# ISP6P5_IPIPE register map
Vendor: Texas Instruments
Peripheral module from a debugger description file (folder TDA2Px).
Registers are 32-bit, access per field, reset 0x0 unless marked. A register's access mark holds for its fields unless they carry their own. Offsets are as the file gives them; lines under a group give offsets from that group; [hi:lo] are bit positions; {n}, {i} and the like mark numbered series; 'fields as' and 'values as' point back to an identical list; <NAME> marks a mode.

## ISP6P5_IPIPE
0x00 IPIPE_SRC_EN — This register is not shadowed
  [0] EN rw — The start flag of the IPIPE module. When EN is 1, the IPIPE module starts a processing from the next rising edge of the VD. If the processing mode of the IPIPE module is ?one shot?, the EN is cleared to 0 immediately after the processing has started.
    0=NEWENUM1 (waiting); 1=NEWENUM2 (start/busy)
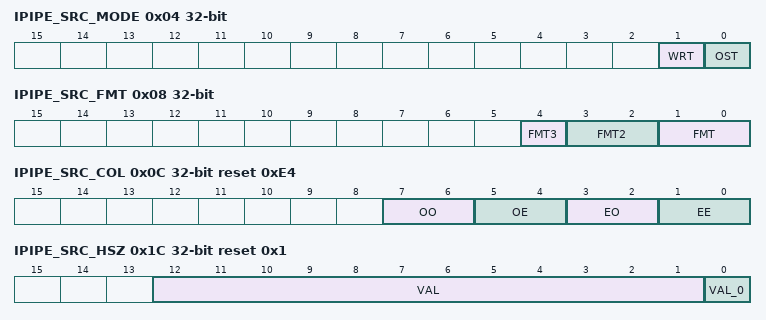
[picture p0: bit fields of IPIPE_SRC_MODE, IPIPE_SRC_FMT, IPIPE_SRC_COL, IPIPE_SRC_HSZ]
0x04 IPIPE_SRC_MODE
  [1] WRT rw — The mode selection of the ipipeif_wrt which is an input port of the IPIPE module. If WRT is 0, the IPIPE module doesn?t use the ipipeif_wrt. Else the IPIPE module uses it.
    0=NEWENUM1 (Disable); 1=NEWENUM2 (Enable)
  [0] OST rw — The processing mode selection of the IPIPE module. Value 0 indicates the mode of ?free run?, value 1 indicates the mode of ?one shot?.
    0=NEWENUM1 (Free run); 1=NEWENUM2 (One shot)
0x08 IPIPE_SRC_FMT
  [4] FMT3 rw — Chroma sumpling postion in YUV422 to 444 This field is only valide if FMT=3 and FT2=2
    0=COSITED (422 to 444 upsampling is processed assuming, chroma pixels are sampled at the same position as Y signals.); 1=CENTERED (422 to 444 upsampling is performed assuming chroma pixels are sampled at the center of two Y signals.)
  [3:2] FMT2 rw — YUV processing mode This field is valid only when FMT=3 (YUV input YUV output)
    0=YUV_PROCESS (Enhanced YUV mode is off. Only EdgeEnhancer, CAR, and CGS are enabled in YUV input); 1=YUV444_MODE (YUV422 input is upconverted to YUV444 422to444 is always used. GBCE, EdgeEnhancer, CAR, CGS, Histogram on YUV, BCS can be enabled.); 2=RGB_MODE (YUV422 input is converted to full color RGB YUVtoRGB (RGBtoRGB1 is used), Gamma (as non linear table), RGB2RGB2, 3DLUT, GBCE are used. EdgeEnhancer, CAR, CGS, Histogram on YUV, BSC can be enabled.)
  [1:0] FMT rw — IPIPE module datapath selection
    0=NEWENUM1 (IN: RAW BAYER OUT: YUV422 Note that the IPIPE YUV422 output goes to the RESIZER module where it can be further be converted in YUV420 or RGB format.); 1=NEWENUM2 (IN: RAW BAYER OUT: RAW BAYER The data are output after the White Balance module. It enables to bypass a large part of the IPIPE module.); 3=NEWENUM4 (IN: YUV422 OUT: YUV422 Note that the IPIPE YUV422 output goes to the RESIZER module where it can be further be converted in YUV420 or RGB format.); 2=NEWENUM3 (IN: RAW BAYER OUT: DISABLED The data are only going to BOXCAR and HISTOGRAM modules.)
0x0C IPIPE_SRC_COL reset 0xE4
  [all] fields
    0=NEWENUM1 (R); 1=NEWENUM2 (Gr); 3=NEWENUM4 (B); 2=NEWENUM3 (Gb)
  [7:6] OO rw — The color pattern of the odd line and odd pixel. This parameter is valid when IPIPE_SRC[FMT] is 0,1,2.
  [5:4] OE rw — The color pattern of the odd line and even pixel. This parameter is valid when IPIPE_SRC[FMT] is 0,1,2.
  [3:2] EO rw — The color pattern of the even line and odd pixel. This parameter is valid when IPIPE_SRC[FMT] is 0,1,2.
  [1:0] EE rw — The color pattern of the even line and even pixel. This parameter is valid when IPIPE_SRC[FMT] is 0,1,2.
0x10 IPIPE_SRC_VPS
  [15:0] VAL rw — The vertical position of the global frame from the rising edge of the VD. The IPIPE module will start an image processing from VAL line.
0x14 IPIPE_SRC_VSZ
  [12:0] VAL rw — The vertical size of the processing area. The VAL0 can not be written. The IPIPE module will process (VAL+1) lines.
0x18 IPIPE_SRC_HPS
  [15:0] VAL rw — The horizontal position of the global frame from the rising edge of the HD. The IPIPE module will start an image processing from VAL clock.
0x1C IPIPE_SRC_HSZ reset 0x1
  [12:1] VAL rw — The horizontal size of the processing area. The VAL0 is fixed. The IPIPE module processes (VAL+1) clocks.
  [0] VAL_0 ro — This is the LSB of the VAL[12:0]. This bit is read only.
0x20 IPIPE_SEL_SBU
  [0] EDOF rw — EDOF port selection
    0=INT (Not used This value must be selected for OMAP4/5/6); 1=EXT (Used Can not be selected for OMAP4/5/6)
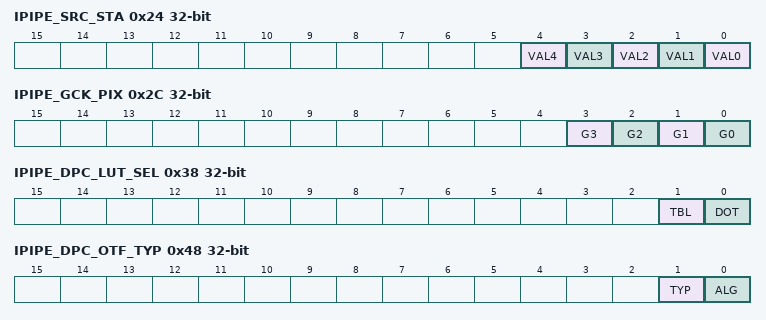
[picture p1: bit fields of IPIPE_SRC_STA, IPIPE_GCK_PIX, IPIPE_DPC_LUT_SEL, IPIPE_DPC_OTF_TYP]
0x24 IPIPE_SRC_STA ro — IPIPE STATUS REGISTER
  [4] VAL4 — Status of Histogram Process (busy status).
  [3] VAL3 — Status of Histogram bank select.
  [2] VAL2 — Status of BSC process (busy status).
  [1] VAL1 — Status of Boxcar process (busy status).
  [0] VAL0 — Status of Boxcar process (error status). This bit will be triggered when an overflow happens while transferring the boxcar data to memory. Instead of polling for this register, it is preferable to use the IPIPE_BOXCAR_OVF interrupt. Overflow errors are non receoverable at ISP5 level and require a software reset at ISS level.
0x28 IPIPE_GCK_MMR
  [0] REG rw — The on/off selection of the clk_arm_g0 which is used for some ARM register access.
    0=NEWENUM1 (Off); 1=NEWENUM2 (On)
0x2C IPIPE_GCK_PIX — This register is not shadowed
  [all] fields
    0=NEWENUM1 (Disable); 1=NEWENUM2 (Enable)
  [3] G3 rw — The on/off selection of the clk_pix_g3 which is use for the IPIPE processes of ?EE? and 'CAR'.
  [2] G2 rw — The on/off selection of the clk_pix_g2 which is use for the IPIPE processes of ?CFA? to '422', 'Histogram(YCbCr input)', and 'Boundary Signal Calculator'.
  [1] G1 rw — The on/off selection of the clk_pix_g1 which is used for the IPIPE processes of 'DefectCorrection' to 'WhiteBalance', and 'Histogram(RAW input)'.
  [0] G0 rw — The on/off selection of the clk_pix_g0 which is used for the IPIPE processing of 'Boxcar'.
0x34 IPIPE_DPC_LUT_EN
  [0] EN rw — Enable of LUT defect pixel correction.
    0=NEWENUM1 (Off); 1=NEWENUM2 (On)
0x38 IPIPE_DPC_LUT_SEL
  [1] TBL rw — LUT table type selection.
    0=NEWENUM1 (Up to 1024 entries. (use)); 1=NEWENUM2 (infinity number of entries. (not use))
  [0] DOT rw — Replace dot selection on processing method 0.
    0=NEWENUM1 (Replace with black dot); 1=NEWENUM2 (Replace with white dot)
0x3C IPIPE_DPC_LUT_ADR
  [9:0] ADR rw — The address of the first valid data in look-up-table
0x40 IPIPE_DPC_LUT_SIZ
  [9:0] SIZ rw — The number of valid data in look-up-table. (SIZ+1)
0x44 IPIPE_DPC_OTF_EN — Enable of adaptive defect pixel correction module.
  [0] EN rw
    0=NEWENUM1 (Off); 1=NEWENUM2 (On)
0x48 IPIPE_DPC_OTF_TYP — To select MinMax Algorithm following values are set ALG: 0 TYP: 0 IPIPE_DPC_OTF_2_D_THR_x: 0 IPIPE_DPC_OTF_2_C_THR_x: maximum value
  [1] TYP rw
    0=NEWENUM1 (with MAX1/MIN1.); 1=NEWENUM2 (with MAX2/MIN2.)
  [0] ALG rw
    0=NEWENUM1 (MinMax2 (DPC2.0)); 1=NEWENUM2 (MinMax3 (DPC3.0))
0x4C IPIPE_DPC_OTF_2_D_THR_R — D_THR for R
  [11:0] VAL rw — Defect detection threshold value for each color (DPC2.0)
0x50 IPIPE_DPC_OTF_2_D_THR_GR — D_THR for Gr
  fields as IPIPE_DPC_OTF_2_D_THR_R
0x54 IPIPE_DPC_OTF_2_D_THR_GB — D_THR for Gb
  fields as IPIPE_DPC_OTF_2_D_THR_R
0x58 IPIPE_DPC_OTF_2_D_THR_B — D_THR for B
  fields as IPIPE_DPC_OTF_2_D_THR_R
0x5C IPIPE_DPC_OTF_2_C_THR_R — C_THR for R
  [11:0] VAL rw — Defect correction threshold value for each color (DPC2.0)
0x60 IPIPE_DPC_OTF_2_C_THR_GR — C_THR for Gr
  fields as IPIPE_DPC_OTF_2_C_THR_R
0x64 IPIPE_DPC_OTF_2_C_THR_GB — C_THR for Gb
  fields as IPIPE_DPC_OTF_2_C_THR_R
0x68 IPIPE_DPC_OTF_2_C_THR_B — C_THR for B
  fields as IPIPE_DPC_OTF_2_C_THR_R
0x6C IPIPE_DPC_OTF_3_SHF
  [1:0] SHF rw
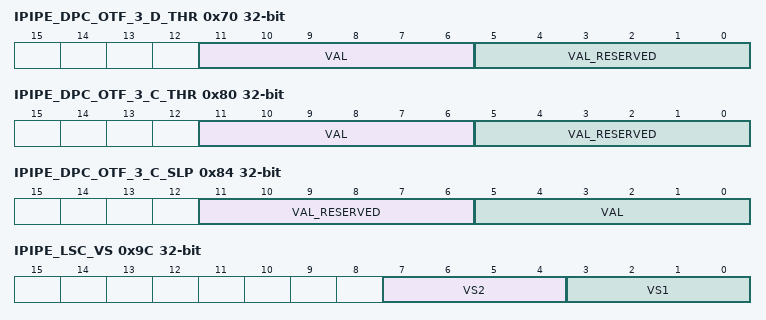
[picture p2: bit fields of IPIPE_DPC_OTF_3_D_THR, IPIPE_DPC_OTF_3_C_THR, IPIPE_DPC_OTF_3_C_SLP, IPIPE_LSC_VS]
0x70 IPIPE_DPC_OTF_3_D_THR
  [11:6] VAL rw — DPC3 Defect detection threshold 12-bit value. Bits [5:0] cannot be written.
  [5:0] VAL_RESERVED ro — DPC3 Defect detection threshold 12-bit value. Bits [5:0] cannot be written.
0x74 IPIPE_DPC_OTF_3_D_SPL
  [5:0] VAL rw — Defect detection threshold slope for DPC3.0
0x78 IPIPE_DPC_OTF_3_D_MIN
  [11:0] VAL rw
0x7C IPIPE_DPC_OTF_3_D_MAX
  [11:0] VAL rw — Defect detection threshold MAX for DPC3.0
0x80 IPIPE_DPC_OTF_3_C_THR
  [11:6] VAL rw — Defect correction threshold for DPC3.0
  [5:0] VAL_RESERVED ro — Defect correction threshold for DPC3.0 Bits VAL[5-0] cannot be written.
0x84 IPIPE_DPC_OTF_3_C_SLP
  [11:6] VAL_RESERVED ro — Defect correction threshold slope for DPC3.0 VAL[11-6] cannot be written.
  [5:0] VAL rw — Defect correction threshold slope for DPC3.0
0x88 IPIPE_DPC_OTF_3_C_MIN
  [11:0] VAL rw — Defect correction threshold MIN for DPC3.0
0x8C IPIPE_DPC_OTF_3_C_MAX
  [11:0] VAL rw — Defect correction threshold MAX for DPC3.0
0x90 IPIPE_LSC_VOFT — LSC VOFT
  [12:0] LSC_VOFT rw
0x94 IPIPE_LSC_VA2
  [12:0] VAL rw — LSC VA2
0x98 IPIPE_LSC_VA1
  [12:0] VAL rw — LSC VA1
0x9C IPIPE_LSC_VS
  [7:4] VS2 rw — LSC VS1
  [3:0] VS1 rw — LSC VS1
0xA0 IPIPE_LSC_HOFT
  [12:0] VAL rw — LSC HOFT
0xA4 IPIPE_LSC_HA2
  [12:0] VAL rw — LSC HA2
0xA8 IPIPE_LSC_HA1
  [12:0] VAL rw — LSC HA1
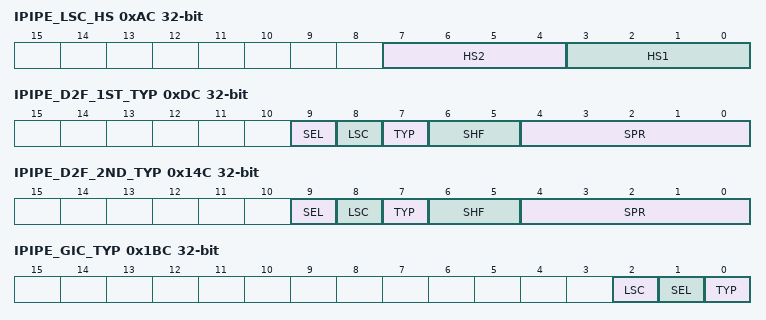
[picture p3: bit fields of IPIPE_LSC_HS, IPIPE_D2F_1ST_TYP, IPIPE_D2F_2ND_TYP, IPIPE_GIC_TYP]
0xAC IPIPE_LSC_HS
  [7:4] HS2 rw — LSC HS1
  [3:0] HS1 rw — LSC HS1
0xB0 IPIPE_LSC_GAN_R
  [7:0] VAL rw — GAN R
0xB4 IPIPE_LSC_GAN_GR
  [7:0] VAL rw — GAN GR
0xB8 IPIPE_LSC_GAN_GB
  [7:0] VAL rw — GAN GB
0xBC IPIPE_LSC_GAN_B
  [7:0] VAL rw — GAN B
0xC0 IPIPE_LSC_OFT_R
  [7:0] VAL rw — LSC OFT R
0xC4 IPIPE_LSC_OFT_GR
  [7:0] VAL rw — LSC OFT GR
0xC8 IPIPE_LSC_OFT_GB
  [7:0] VAL rw — LSC OFT GB
0xCC IPIPE_LSC_OFT_B
  [7:0] VAL rw — LSC OFT B
0xD0 IPIPE_LSC_SHF
  [3:0] VAL rw — LSC SHV
0xD4 IPIPE_LSC_MAX
  [8:0] VAL rw — LSC MAX
0xD8 IPIPE_D2F_1ST_EN — Noise Filter 1 Register
  [0] EN rw — Enable of noise filter-1 module.
    0=NEWENUM1 (off); 1=NEWENUM2 (on)
0xDC IPIPE_D2F_1ST_TYP — Noise Filter 1 Register
  [9] SEL rw — Select SPR value source
    0=NEWENUM1 (use single SPR value); 1=NEWENUM2 (use LUT SPR values)
  [8] LSC rw — Apply LSC gain to threshold values
    0=NEWENUM1 (off); 1=NEWENUM2 (on)
  [7] TYP rw — The sampling method of green pixels.
    0=NEWENUM1 (Box (same as R or B)); 1=NEWENUM2 (Diamond mode)
  [6:5] SHF rw — The d value (down shift value) in look-up-table reference address.
  [4:0] SPR rw — The SP value ('spread' value) in noise filter-1 algorithm.
{0xE0+4i} IPIPE_D2F_1ST_THR_{i:02} (i=0..7) — Noise Filter 1 Register
  [9:0] VAL rw — Threshold values in noise filter-1 algorithm.
{0x100+4i} IPIPE_D2F_1ST_STR_{i:02} (i=0..7) — Noise Filter 1 Register
  [4:0] VAL rw — Noise filter-1 intensity values (STR).
{0x120+4i} IPIPE_D2F_1ST_SPR_{i:02} (i=0..7) — Noise Filter 1 Register
  [4:0] VAL rw — Noise filter-1 intensity values (SP). The value is in U3.5 format.
0x140 IPIPE_D2F_1ST_EDG_MIN — Noise Filter 1 Register
  [10:0] VAL rw — Noise filter-1 edge detection MIN
0x144 IPIPE_D2F_1ST_EDG_MAX — Noise Filter 1 Register
  [10:0] VAL rw — Noise filter-1 edge detection MAX
0x148 IPIPE_D2F_2ND_EN — Noise Filter 2 Register
  [0] EN rw — Enable of noise filter-2 module.
    0=NEWENUM1 (off); 1=NEWENUM2 (on)
0x14C IPIPE_D2F_2ND_TYP — Noise Filter 2 Register
  [9] SEL rw — Select SPR value source
    values as IPIPE_D2F_1ST_TYP.SEL
  [8] LSC rw — Apply LSC gain to threshold values
    0=NEWENUM1 (off); 1=NEWENUM2 (on)
  [7] TYP rw — The sampling method of green pixels.
    0=NEWENUM1 (Box (Same as R or B)); 1=NEWENUM2 (Diamond mode)
  [6:5] SHF rw — The d value (down shift value) in look-up-table reference address.
  [4:0] SPR rw — The SP value ('spread' value) in noise filter-2 algorithm.
{0x150+4i} IPIPE_D2F_2ND_THR{i:02} (i=0..7) — Noise Filter 2 Register
  [9:0] VAL rw — Threshold values in noise filter-2 algorithm.
{0x170+4i} IPIPE_D2F_2ND_STR_{i:02} (i=0..7) — Noise Filter 2 Register
  [4:0] VAL rw — Noise filter-2 intensity values (STR).
{0x190+4i} IPIPE_D2F_2ND_SPR_{i:02} (i=0..7) — Noise Filter 2 Register
  [4:0] VAL rw — Noise filter-2 intensity values (SP). The value is in U3.5 format.
0x1B0 IPIPE_D2F_2ND_EDG_MIN — Noise Filter 2 Register
  [10:0] VAL rw — Noise filter-2 edge detection MIN
0x1B4 IPIPE_D2F_2ND_EDG_MAX — Noise Filter 2 Register
  [10:0] VAL rw — Noise filter-2 edge detection MAX
0x1B8 IPIPE_GIC_EN — Green Imbalance Correction Register
  [0] EN rw — Enable signal of PreFilter module
    0=NEWENUM1 (off); 1=NEWENUM2 (on)
0x1BC IPIPE_GIC_TYP — Green Imbalance Correction Register
  [2] LSC rw — Applies LSC gain to threshold value
    0=NEWENUM1 (Disable); 1=NEWENUM2 (Enable)
  [1] SEL rw — Threshold Selection This bit selects the threshold either from the register value (GIC_THR) or threshold table of NF-2
    0=NEWENUM1 (use GIC register value); 1=NEWENUM2 (use NF2 threshold)
  [0] TYP rw — Algorithm select
    0=NEWENUM1 (Use differencce as index); 1=NEWENUM2 (Use 1D high-pass value as index)
0x1C0 IPIPE_GIC_GAN — Green Imbalance Correction Register
  [7:0] VAL rw — VAL specifies the PreFilter gain.
0x1C4 IPIPE_GIC_NFGAIN
  [7:0] VAL rw
0x1C8 IPIPE_GIC_THR — Green Imbalance Correction Register
  [11:0] VAL rw — Threshold-1 in the adaptive GIC algorithm. For constant gain mode, setIPIPE_GIC_THR=maximum value.
0x1CC IPIPE_GIC_SLP — Green Imbalance Correction Register
  [11:0] VAL rw — Slope (THR2-THR1) of GIC algorithm.
0x1D0 IPIPE_WB2_OFT_R — White Balance Register
  [11:0] VAL rw — Offset before white balance (S12) -2048 to +2047
0x1D4 IPIPE_WB2_OFT_GR — White Balance Register
  [11:0] VAL rw — Offset before white balance (S12) -2048 to +2047
0x1D8 IPIPE_WB2_OFT_GB — White Balance Register
  [11:0] VAL rw — Offset before white balance (S12) -2048 to +2047
0x1DC IPIPE_WB2_OFT_B — White Balance Register
  [11:0] VAL rw — Offset before white balance (S12) -2048 to +2047
0x1E0 IPIPE_WB2_WGN_R reset 0x200 — White Balance Register
  [12:0] VAL rw — White balance gain for R in U4.9 format 0 to +15.998
0x1E4 IPIPE_WB2_WGN_GR reset 0x200 — White Balance Register
  [12:0] VAL rw — White balance gain for Gr in U4.9 format 0 to +15.998
0x1E8 IPIPE_WB2_WGN_GB reset 0x200 — White Balance Register
  [12:0] VAL rw — White balance gain for Gb in U4.9 format 0 to +15.998
0x1EC IPIPE_WB2_WGN_B reset 0x200 — White Balance Register
  [12:0] VAL rw — White balance gain for B in U4.9 format 0 to +15.998
0x1F0 IPIPE_CFA_MODE — CFA Register
  [1:0] MODE rw — Algorithm selection
    0=NEWENUM1 (2DirAC); 1=NEWENUM2 (2DirAC + DigitalAntialiasing (DAA)); 3=NEWENUM4 (Co-sited Bayer format Sets the CFA in co-sited Bayer format: the sampling points of R/Gr/Gb/B in each 2x2 block is at the same position. In this mode, the CFA interpolator simply copies R, G, and B to all points in the 2x2 block. (G is an average of Gb and Gr.)); 2=NEWENUM3 (DigitalAntialiasing (DAA))
0x1F4 IPIPE_CFA_2DIR_HPF_THR — CFA: HP Value Low Threshold
  [12:0] VAL rw — HPF_THR 2DirCFA HP Value Low Threshold
0x1F8 IPIPE_CFA_2DIR_HPF_SLP — CFA: HP Value Slope
  [9:0] VAL rw — HPF_SLP 2DirCFA HP Value Slope
0x1FC IPIPE_CFA_2DIR_MIX_THR — CFA: HP Mix Threshold
  [12:0] VAL rw — MIX_THR 2DirCFA HP Mix Threshold
0x200 IPIPE_CFA_2DIR_MIX_SLP — CFA Register
  [9:0] VAL rw — MIX_SLP 2DirCFA HP Mix Slope
0x204 IPIPE_CFA_2DIR_DIR_TRH — CFA: Direction Threshold
  [9:0] VAL rw — DIR_THR 2DirCFA Direction Threshold
0x208 IPIPE_CFA_2DIR_DIR_SLP — CFA: Direction Slope
  [6:0] VAL rw — DIR_SLP 2DirCFA Direction Slope
0x20C IPIPE_CFA_2DIR_NDWT
  [5:0] VAL rw — ND Weight 2DirCFA NonDirectional Weight
0x210 IPIPE_CFA_MONO_HUE_FRA — Mono CFA Register
  [5:0] VAL rw — HUE_FRA DAA Hue Fraction
0x214 IPIPE_CFA_MONO_EDG_THR — monoCFA THR SLP
  [7:0] VAL rw — EDGE_THR DAA Edge Threshold
0x218 IPIPE_CFA_MONO_THR_MIN — Mono CFA Register
  [9:0] VAL rw — THR_MIN DAA Threshold Minimum
0x21C IPIPE_CFA_MONO_THR_SLP — CFA: Threshold Slope
  [9:0] VAL rw — THR_SLP DAA Threshold Slope
0x220 IPIPE_CFA_MONO_SLP_MIN — CFA: Threshold Minimum
  [9:0] VAL rw — SLP_MIN DAA Slope Minimum
0x224 IPIPE_CFA_MONO_SLP_SLP — CFA: Threshold Slope
  [9:0] VAL rw — SLP_SLP DAA Slope Slope
0x228 IPIPE_CFA_MONO_LPWT — CFA: LP Weight
  [5:0] VAL rw — LPWT DAA LP Weight
0x22C IPIPE_RGB1_MUL_RR reset 0x100 — RGB to RGB Conversion Register
  [11:0] VAL rw — The matrix coefficient. 011111111111 = 2047/256 = 7.99609375 011111111110 = 2046/256 [...] 000011111111 = 255/256 000100000000 = 256/256 = 1 000100000001 = 257/256 [...] 000000000001 = 1/256 000000000000 = 0/256 = 0 111111111111 = -1/256 = -0.00390625 111111111110 = -2/256 [...] 100000000001 = -2047/256 100000000000 = -2048/256 = -8.
0x230 IPIPE_RGB1_MUL_GR — RGB to RGB Conversion Register
  [11:0] VAL rw — The matrix coefficient.
0x234 IPIPE_RGB1_MUL_BR — RGB to RGB Conversion Register
  [11:0] VAL rw — The matrix coefficient.
0x238 IPIPE_RGB1_MUL_RG — RGB to RGB Conversion Register
  [11:0] VAL rw — The matrix coefficient.
0x23C IPIPE_RGB1_MUL_GG reset 0x100 — RGB to RGB Conversion Register
  [11:0] VAL rw — The matrix coefficient.
0x240 IPIPE_RGB1_MUL_BG — RGB to RGB Conversion Register
  [11:0] VAL rw — The matrix coefficient.
0x244 IPIPE_RGB1_MUL_RB — RGB to RGB Conversion Register
  [11:0] VAL rw — The matrix coefficient.
0x248 IPIPE_RGB1_MUL_GB — RGB to RGB Conversion Register
  [11:0] VAL rw — The matrix coefficient.
0x24C IPIPE_RGB1_MUL_BB reset 0x100 — RGB to RGB Conversion Register
  [11:0] VAL rw — The matrix coefficient.
0x250 IPIPE_RGB1_OFT_OR — RGB to RGB Conversion Register
  [12:0] VAL rw — The output offset value for R. (s13) -4096 to +4095
0x254 IPIPE_RGB1_OFT_OG — RGB to RGB Conversion Register
  [12:0] VAL rw — The output offset value for G. (s13) -4096 to +4095
0x258 IPIPE_RGB1_OFT_OB — RGB to RGB Conversion Register
  [12:0] VAL rw — The output offset value for B. (s13) -4096 to +4095
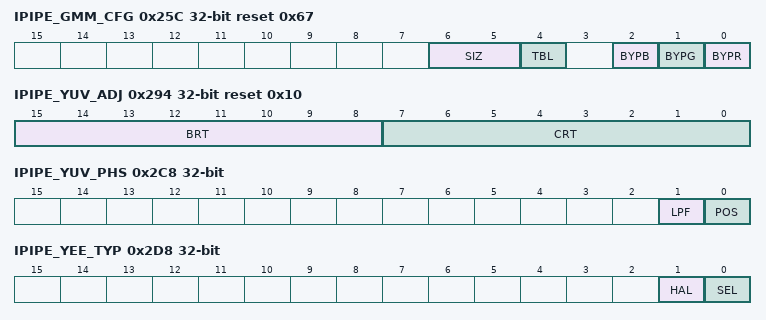
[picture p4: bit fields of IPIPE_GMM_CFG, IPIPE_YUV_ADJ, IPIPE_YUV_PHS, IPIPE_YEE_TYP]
0x25C IPIPE_GMM_CFG reset 0x67 — RGB to RGB Conversion Register
  [6:5] SIZ rw — The size of the gamma table.
    0=NEWENUM1 (64 words); 1=NEWENUM2 (128 words); 3=NEWENUM4 (512 words); 2=NEWENUM3 (256 words)
  [4] TBL rw — Selection of Gamma table.
    0=NEWENUM1 (RAM); 1=NEWENUM2 (ROM)
  [2] BYPB rw — Gamma correction mode for B
    0=NEWENUM1 (Not bypassed); 1=NEWENUM2 (Bypassed)
  [1] BYPG rw — Gamma correction mode for G
    0=NEWENUM1 (Not bypassed); 1=NEWENUM2 (Bypassed)
  [0] BYPR rw — Gamma correction mode for R
    0=NEWENUM1 (Not bypassed); 1=NEWENUM2 (Bypassed)
0x260 IPIPE_RGB2_MUL_RR reset 0x100 — RGB to RGB conversion after gamma
  [10:0] VAL rw — The matrix coefficient. 011111111111 = 2047/256 = 7.99609375 011111111110 = 2046/256 000011111111 = 255/256 000100000000 = 256/256 = 1 000100000001 = 257/256 000000000001 = 1/256 000000000000 = 0/256 = 0 111111111111 = -1/256 = -0.00390625 111111111110 = -2/256 100000000001 = -2047/256 100000000000 = -2048/256 = -8.
0x264 IPIPE_RGB2_MUL_GR — RGB to RGB conversion after gamma
  [10:0] VAL rw — The matrix coefficient.
0x268 IPIPE_RGB2_MUL_BR — RGB to RGB conversion after gamma
  [10:0] VAL rw — The matrix coefficient.
0x26C IPIPE_RGB2_MUL_RG — RGB to RGB conversion after gamma
  [10:0] VAL rw — The matrix coefficient.
0x270 IPIPE_RGB2_MUL_GG reset 0x100 — RGB to RGB conversion after gamma
  [10:0] VAL rw — The matrix coefficient.
0x274 IPIPE_RGB2_MUL_BG — RGB to RGB conversion after gamma
  [10:0] VAL rw — The matrix coefficient.
0x278 IPIPE_RGB2_MUL_RB — RGB to RGB conversion after gamma
  [10:0] VAL rw — The matrix coefficient.
0x27C IPIPE_RGB2_MUL_GB — RGB to RGB conversion after gamma
  [10:0] VAL rw — The matrix coefficient.
0x280 IPIPE_RGB2_MUL_BB reset 0x100 — RGB to RGB conversion after gamma
  [10:0] VAL rw — The matrix coefficient.
0x284 IPIPE_RGB2_OFT_OR — RGB to RGB conversion after gamma
  [10:0] VAL rw — The output offset value for R S10 number: -1024 to + 1023
0x288 IPIPE_RGB2_OFT_OG — RGB to RGB conversion after gamma
  [10:0] VAL rw — The output offset value for G S10 number: -1024 to + 1023
0x28C IPIPE_RGB2_OFT_OB — RGB to RGB conversion after gamma
  [10:0] VAL rw — The output offset value for B S10 number: -1024 to + 1023
0x290 IPIPE_3DLUT_EN — 3D-LUT
  [0] EN rw — Enables or disable the 3D-LUT function. The table entries are store in internal memory.
    0=NEWENUM1 (Disable); 1=NEWENUM2 (Enable)
0x294 IPIPE_YUV_ADJ reset 0x10 — RGB to YUV Conversion Register
  [15:8] BRT rw — The offset value for brightness control.
  [7:0] CRT rw — The multiplier coefficient value for contrast control. 00000000 = 0/16 = 0 00000001 = 1/16 00001111 = 15/16 00010000 = 16/16 = 1 00010001 = 17/16 11111110 = 254/16 11111111 = 255/16 = 15.9375
0x298 IPIPE_YUV_MUL_RY reset 0x4D — RGB to YUV Conversion Register
  [11:0] VAL rw — Matrix Coefficient for RY (S4.8 = -8 - +7.996)
0x29C IPIPE_YUV_MUL_GY reset 0x96 — RGB to YUV Conversion Register
  [11:0] VAL rw — Matrix Coefficient for GY (S4.8 = -8 - +7.996)
0x2A0 IPIPE_YUV_MUL_BY reset 0x1D — RGB to YUV Conversion Register
  [11:0] VAL rw — Matrix Coefficient for BY (S4.8 = -8 - +7.996)
0x2A4 IPIPE_YUV_MUL_RCB reset 0xFD5 — RGB to YUV Conversion Register
  [11:0] VAL rw — The matrix coefficient.
0x2A8 IPIPE_YUV_MUL_GCB reset 0xFAB — RGB to YUV Conversion Register
  [11:0] VAL rw — The matrix coefficient.
0x2AC IPIPE_YUV_MUL_BCB reset 0x80 — RGB to YUV Conversion Register
  [11:0] VAL rw — The matrix coefficient.
0x2B0 IPIPE_YUV_MUL_RCR reset 0x80 — RGB to YUV Conversion Register
  [11:0] VAL rw — The matrix coefficient.
0x2B4 IPIPE_YUV_MUL_GCR reset 0xF95 — RGB to YUV Conversion Register
  [11:0] VAL rw — The matrix coefficient.
0x2B8 IPIPE_YUV_MUL_BCR reset 0xFEB — RGB to YUV Conversion Register
  [11:0] VAL rw — The matrix coefficient.
0x2BC IPIPE_YUV_OFT_Y — RGB to YUV Conversion Register
  [10:0] VAL rw — The output offset value for Y
0x2C0 IPIPE_YUV_OFT_CB reset 0x80 — RGB to YUV Conversion Register
  [10:0] VAL rw — The output offset value for Cb For Cb/Cr, set (0x80 + offset value) here. (0x80 for zero offset.)
0x2C4 IPIPE_YUV_OFT_CR reset 0x80 — RGB to YUV Conversion Register
  [10:0] VAL rw — The output offset value for Cr For Cb/Cr, set (0x80 + offset value) here. (0x80 for zero offset.)
0x2C8 IPIPE_YUV_PHS — YUV422 down sampling register. This register controls the YUV444 to YUV422 chroma downsampling. This register is valid if.FMT = 0 (RAW input and YUV output). = 0 leads to pure subsampling, no filtering, cosited chroma output. = 1 leads to (1, 1) 1 filtering, centered chroma output. = 2 leads to (1, 2, 1) 1 filtering, cosited chroma output. = 3 leads to (1, 3, 3, 1) 3 filtering, centered chroma output. When the chroma output is cosited, and that downsampling is enabled in the RESIZER module, one need to take care that the averager disrupts the relative phase for luma and chroma color components. The and registers need to be used to fix the disruption.
  [1] LPF rw — 121-LPF enable for chrominance samples. This register is valid ifIPIPE_SRC_FMT.FMT = 0 (RAW input and YUV output).
    0=NEWENUM1 (off); 1=NEWENUM2 (on)
  [0] POS rw — This bit sets the output position of the chrominance sample with regards to the luma sample positions. One can choose between centered and cosited. This register is valid ifIPIPE_SRC_FMT.FMT = 0 (RAW input and YUV output). The RESIZER module does not change the relative position of the chroma samples vs. the luma samples between the input and output and the chroma position at the output of the IPIPE module and at the output of the RESIZER module shall be identical. In other words, we shall have RSZ_YUV_PHS.POS = IPIPE_YUV_PHS.POS.
    0=NEWENUM1 (Cosited = same position with luminance); 1=NEWENUM2 (Centered = middle of the luminance)
0x2CC IPIPE_GBCE_EN — Global brightness contrast enhancement
  [0] EN rw — Enable of GBCE module.
    0=NEWENUM1 (Off); 1=NEWENUM2 (On)
0x2D0 IPIPE_GBCE_TYP — Global brightness contrast enhancement
  [0] TYP rw — GBCE method selection
    0=NEWENUM1 (Y value table Y out= LUT[Y in] Cb out = Cb in Cr out = Cr in); 1=NEWENUM2 (Gain table Y out= LUT[Y in] * Y in Cb out = LUT[Y in] * Cb in Cr out = LUT[Y in] * Cr in)
0x2D4 IPIPE_YEE_EN — Edge Enhancer Register
  [0] EN rw — The on/off selection of the ?Edge enhancer?.
    0=NEWENUM1 (Disable); 1=NEWENUM2 (Enable)
0x2D8 IPIPE_YEE_TYP — Edge Enhancer Register
  [1] HAL rw — Halo reduction in Edge Sharpener module
  [0] SEL rw — Merging method between Edge Enhancer and Edge Sharpener
    0=NEWENUM2 (EE + ES); 1=NEWENUM1 (Max (EE, ES))
0x2DC IPIPE_YEE_SHF — Edge Enhancer Register
  [3:0] SHF rw — Down shift length of high pass filter (HPF) in edge enhancer.
0x2E0 IPIPE_YEE_MUL_00 — Edge Enhancer Register
  [9:0] VAL rw — Multiplier coefficient in HPF. 0111111111 = 511 0111111110 = 510 0000000001 = 1 0000000000 = 0 1111111111 = -1 1000000001 = -511 1000000000 = -512
0x2E4 IPIPE_YEE_MUL_01 — Edge Enhancer Register
  [9:0] VAL rw — Multiplier coefficient in HPF.
0x2E8 IPIPE_YEE_MUL_02 — Edge Enhancer Register
  [9:0] VAL rw — Multiplier coefficient in HPF.
{0x2C4+4i} IPIPE_YEE_MUL_{i} (i=10..12) — Edge Enhancer Register
  [9:0] VAL rw — Multiplier coefficient in HPF.
{0x2A8+4i} IPIPE_YEE_MUL_{i} (i=20..22) — Edge Enhancer Register
  [9:0] VAL rw — Multiplier coefficient in HPF.
0x304 IPIPE_YEE_THR — Edge Enhancer Register
  [5:0] VAL rw — Edge Enhancer lower threshold before referring to LUT. If HPF -IPIPE_YEE_THR - output is HPF + IPIPE_YEE_THR If HPF IPIPE_YEE_THR - output is HPF - IPIPE_YEE_THR Otherwise, output is zero.
0x308 IPIPE_YEE_E_GAN — Edge Enhancer Register
  [11:0] VAL rw — Edge sharpener gain
0x30C IPIPE_YEE_E_THR_1 — Edge Enhancer Register
  [11:0] VAL rw — Edge sharpener HPF value lower limit
0x310 IPIPE_YEE_E_THR_2 — Edge Enhancer Register
  [5:0] VAL rw — Edge sharpener HPF value upper limit (after 6 bit right shift)
0x314 IPIPE_YEE_G_GAN — Edge Enhancer Register
  [7:0] VAL rw — Edge sharpener, gain value on gradient
0x318 IPIPE_YEE_G_OFT — Edge Enhancer Register
  [5:0] VAL rw — Edge sharpener, offset value on gradient
0x31C IPIPE_CAR_EN — Chroma Artifact Reduction Register
  [0] EN rw — The on/off selection of the ?fault color suppression?. When the RSZ_SRC_FMT.FMT0='1' (Bayer input, Bayer output), this bit must be 0.
    0=NEWENUM1 (Disable); 1=NEWENUM2 (Enable)
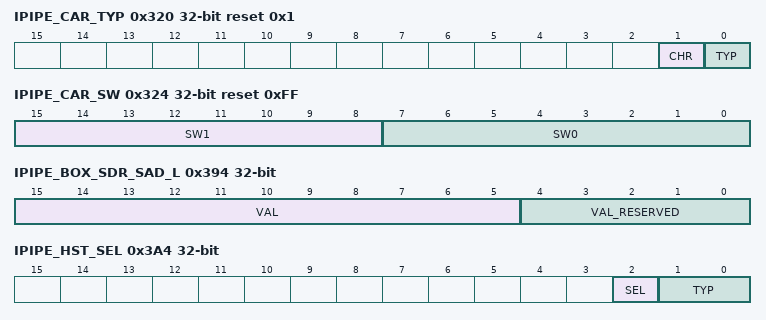
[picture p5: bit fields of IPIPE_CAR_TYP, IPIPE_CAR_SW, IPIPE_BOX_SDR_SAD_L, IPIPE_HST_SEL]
0x320 IPIPE_CAR_TYP reset 0x1 — Chroma Artifact Reduction Register
  [1] CHR rw — Note: This bit is added to OMAP5430 release and after. To specify the order of chroma in dynamic switching. This value should be zero unless Cb and Cr is flipped at RGBtoYCbCr/ 0: Normal Cb/Cr order (default) 1: Flipped order (Cr/Cb)
    0=NEWENUM1 (Default Chroma order (Cb/Cr).); 1=NEWENUM2 (Flipped chroma order (Cr/Cb). This value is used only when Cb and Cr are flipped in RGBtoYUV module.)
  [0] TYP rw — The mode selection of the ?fault color suppression?. To select median filter, set TYP=1 and IPIPE_CAR_SWT.SW0=255 (default values)
    0=NEWENUM1 (Gain control); 1=NEWENUM2 (Dynamic switching)
0x324 IPIPE_CAR_SW reset 0xFF — Chroma Artifact Reduction Register
  [15:8] SW1 rw — Threshold-2 for switching function (Select gain control)
  [7:0] SW0 rw — Threshold-1 for switching function (Select median filter)
0x328 IPIPE_CAR_HPF_TYP — Chroma Artifact Reduction Register
  [2:0] TYP rw
    6=NEWENUM7 (Reserved); 1=NEWENUM2 (Horiz HPF); 7=NEWENUM8 (Reserved); 0=NEWENUM1 (Y); 2=NEWENUM3 (Vert HPF); 4=NEWENUM5 (2D HPF from edge enhancer); 5=NEWENUM6 (Reserved); 3=NEWENUM4 (2D HPF)
0x32C IPIPE_CAR_HPF_SHF — Chroma Artifact Reduction Register
  [1:0] VAL rw — Down shift value for HPF.
0x330 IPIPE_CAR_HPF_THR — Chroma Artifact Reduction Register
  [7:0] VAL rw — The threshold of the gain function for HPF value
0x334 IPIPE_CAR_GN1_GAN — Chroma Artifact Reduction Register
  [7:0] VAL rw — The intensity of the gain function for HPF value
0x338 IPIPE_CAR_GN1_SHF — Chroma Artifact Reduction Register
  [2:0] VAL rw — The down shift value of the gain function on HPF value
0x33C IPIPE_CAR_GN1_MIN — Chroma Artifact Reduction Register
  [8:0] VAL rw — The lower limit of the gain function on HPF value
0x340 IPIPE_CAR_GN2_GAN — Chroma Artifact Reduction Register
  [7:0] VAL rw — The intensity of the gain function for chroma value
0x344 IPIPE_CAR_GN2_SHF — Chroma Artifact Reduction Register
  [3:0] VAL rw — The down shift value of the gain function on chroma value
0x348 IPIPE_CAR_GN2_MIN — Chroma Artifact Reduction Register
  [8:0] VAL rw — The lower limit of the gain function on chroma value
0x34C IPIPE_CGS_EN — Chroma Gain Suppression
  [0] EN rw — Enables or disables chroma gain suppression
    0=NEWENUM1 (Disable); 1=NEWENUM2 (Enable)
0x350 IPIPE_CGS_GN1_L_THR — Chroma Gain Suppression
  [7:0] VAL rw
0x354 IPIPE_CGS_GN1_L_GAIN — Chroma Gain Suppression
  [7:0] VAL rw
0x358 IPIPE_CGS_GN1_L_SHF — Chroma Gain Suppression
  [2:0] VAL rw
0x35C IPIPE_CGS_GN1_L_MIN — Chroma Gain Suppression
  [7:0] VAL rw — The lower limit 1 of the gain function 1
0x360 IPIPE_CGS_GN1_H_THR — Chroma Gain Suppression
  [7:0] VAL rw — The threshold 2 of the gain function for Y value
0x364 IPIPE_CGS_GN1_H_GAIN — Chroma Gain Suppression
  [7:0] VAL rw — The slope 2 of the gain function for Y value
0x368 IPIPE_CGS_GN1_H_SHF — Chroma Gain Suppression
  [2:0] VAL rw — The down shift value of the gain function on Y
0x36C IPIPE_CGS_GN1_H_MIN — Chroma Gain Suppression
  [7:0] VAL rw — The lower limit 2 of the gain function
0x370 IPIPE_CGS_GN2_L_THR — Chroma Gain Suppression
  [7:0] VAL rw — The slope 2 of the gain function for Y value
0x374 IPIPE_CGS_GN2_L_GAIN — Chroma Gain Suppression
  [7:0] VAL rw — The down shift value 3 of the gain function on Y
0x378 IPIPE_CGS_GN2_L_SHF
  [2:0] VAL rw
0x37C IPIPE_CGS_GN2_L_MIN — Chroma Gain Suppression
  [7:0] VAL rw — The lower limit 3 of the gain function
0x380 IPIPE_BOX_EN — Boxcar Register
  [0] EN rw — This bit enables ordisables the BOXCAR functionality. The BOXCAR output is written to SDRAM. One need to set theIPIPE_BOX_SDR_SAD_H and IPIPE_BOX_SDR_SAD_L registers with the appropriate address.
    0=NEWENUM1 (Disable); 1=NEWENUM2 (Enable)
0x384 IPIPE_BOX_MODE — Boxcar Register
  [0] OST rw — The processing mode selection of the Boxcar function. A 0 indicates the mode of the ?free run?, a 1 indicates the mode of the ?one shot'.
    0=NEWENUM1 (Free run); 1=NEWENUM2 (One shot)
0x388 IPIPE_BOX_TYP — Boxcar Register
  [0] SEL rw — Block size in boxcar sampling
    0=NEWENUM1 (8x8); 1=NEWENUM2 (16x16)
0x38C IPIPE_BOX_SHF — Boxcar Register
  [2:0] VAL rw — The down shift value applied to the boxcar compuation result. R out = SUM (Rij) SHF G out = (SUM (Gr ij)/2 + SUM (Gr ij)/2) SHF B out = SUM (Gij) SHF
0x390 IPIPE_BOX_SDR_SAD_H — Boxcar Register
  [15:0] VAL rw — The higher 11 bits of the first address of output in memory.
0x394 IPIPE_BOX_SDR_SAD_L — Boxcar Register
  [15:5] VAL rw — The lower 16 bits of the first address of output in memory.
  [4:0] VAL_RESERVED ro — Ensures 32-byte alignment.
0x39C IPIPE_HST_EN — Histogram
  [0] EN rw — This bit enables or disables the HISTOGRAM functionality. When enabled, the HISTOGRAM computation will start the processing from the next rising edge of the VD pulse. If the processing mode of the HISTOGRAM is ?one shot?, the enable bit will be cleared to 0 immediately after the processing has started.
    0=NEWENUM1 (disable); 1=NEWENUM2 (start/busy)
0x3A0 IPIPE_HST_MODE — Histogram
  [0] OST rw — The processing mode selection of the Histogram module. A 0 indicates the mode of the ?free run?, a 1 indicates the mode of the ?one shot'.
    0=NEWENUM1 (Free run); 1=NEWENUM2 (One shot)
0x3A4 IPIPE_HST_SEL — Histogram
  [2] SEL rw — Input selection. When SEL0=0, RGBY are sampled from the output of the line buffer in noise filter-2. When SEL0=1, YCbCr are sampled at the output of RGB2YCbCr module. Y is sampled twice.
    0=NEWENUM1 (From noise filter input); 1=NEWENUM2 (From RGBtoYUV)
  [1:0] TYP rw — G selection in Bayer mode (SEL0=0)
    0=NEWENUM1 (Gb); 1=NEWENUM2 (Gr); 3=NEWENUM4 (Reserved); 2=NEWENUM3 ((Gb+Gr)/2)
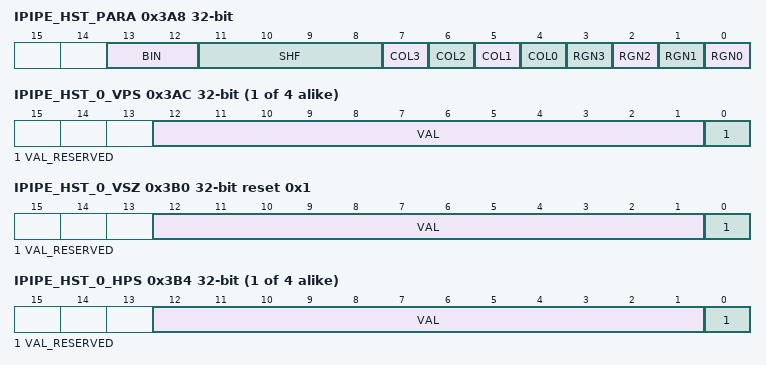
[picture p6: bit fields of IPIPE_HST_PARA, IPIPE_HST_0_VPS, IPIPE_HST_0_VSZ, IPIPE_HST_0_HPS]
0x3A8 IPIPE_HST_PARA — Histogram COL0, COL1, COL2, and COL3 should be set to ?1?.
  [13:12] BIN rw — The number of the bins.
    0=NEWENUM1 (32); 1=NEWENUM2 (64); 3=NEWENUM4 (256); 2=NEWENUM3 (128)
  [11:8] SHF rw — The shift length of the input data. data = (INPUT SHF)
  [7] COL3 rw — The on/off selection of the color pattern 3 (Y).
    0=NEWENUM1 (Disable); 1=NEWENUM2 (Enable)
  [6] COL2 rw — The on/off selection of the color pattern 2 (B).
    0=NEWENUM1 (Disable); 1=NEWENUM2 (Enable)
  [5] COL1 rw — The on/off selection of the color pattern 1 (G).
    0=NEWENUM1 (Disable); 1=NEWENUM2 (Enable)
  [4] COL0 rw — The on/off selection of the color pattern 0 (R).
    0=NEWENUM1 (Disable); 1=NEWENUM2 (Enable)
  [n] RGN{n} rw (n=0..3) — The on/off selection of the region {n}.
    0=NEWENUM1 (Disable); 1=NEWENUM2 (Enable)
{0x3AC+0x10*i} IPIPE_HST_{i}_VPS (i=0..3) — Histogram
  [12:1] VAL rw — The vertical position of the region 0 from theIPIPE_SRC_VPS. The region {i} will start the ?Histogram? processing from VAL line. VAL[0] can not be written.
  [0] VAL_RESERVED ro — The vertical position of the region 0 from theIPIPE_SRC_VPS. The region {i} will start the ?Histogram? processing from VAL line. VAL[0] can not be written.
0x3B0 IPIPE_HST_0_VSZ reset 0x1 — Histogram
  [12:1] VAL rw — The vertical size of the region 0. The ?Histogram? processing of the region 0 will process (VAL+1) lines.
  [0] VAL_RESERVED ro — The vertical size of the region 0. The ?Histogram? processing of the region 0 will process (VAL+1) lines. VAL[0] cannot be written.
{0x3B4+0x10*i} IPIPE_HST_{i}_HPS (i=0..3) — Histogram
  [12:1] VAL rw — The horizontal position of the region 0 from theIPIPE_SRC_HPS. The region {i} will start the ?Histogram? processing from VAL clocks. VAL[0] can not be written.
  [0] VAL_RESERVED ro — The horizontal position of the region 0 from theIPIPE_SRC_HPS. The region {i} will start the ?Histogram? processing from VAL clocks. VAL[0] can not be written.
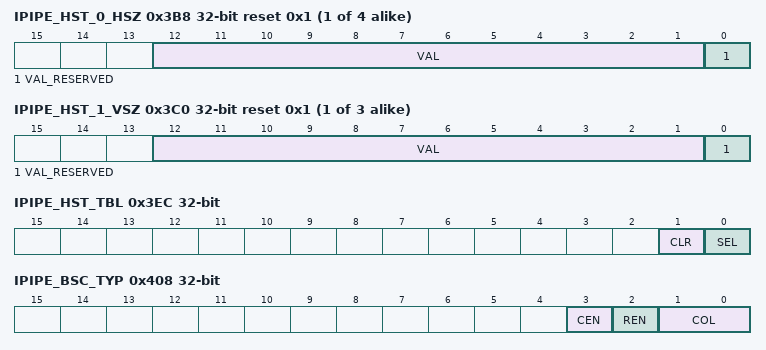
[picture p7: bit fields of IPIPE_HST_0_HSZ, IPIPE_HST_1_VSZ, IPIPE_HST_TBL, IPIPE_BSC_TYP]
{0x3B8+0x10*i} IPIPE_HST_{i}_HSZ reset 0x1 (i=0..3) — Histogram
  [12:1] VAL rw — The horizontal size of the region {i}. The ?Histogram? processing of the region {i} will process (VAL+1) clocks. VAL[0] cannot be written.
  [0] VAL_RESERVED ro — The horizontal size of the region {i}. The ?Histogram? processing of the region {i} will process (VAL+1) clocks. VAL[0] cannot be written.
{0x3B0+0x10*i} IPIPE_HST_{i}_VSZ reset 0x1 (i=1..3) — Histogram
  [12:1] VAL rw — The vertical size of the region {i}. The ?Histogram? processing of the region {i} will process (VAL+1) lines. VAL[0] cannot be written.
  [0] VAL_RESERVED ro — The vertical size of the region {i}. The ?Histogram? processing of the region {i} will process (VAL+1) lines. VAL[0] cannot be written.
0x3EC IPIPE_HST_TBL — Histogram
  [1] CLR rw — Histogram memory clear. The histogram can be cleared before the start of operations. However, the clear takes 512 cycles and therfore: + if line size 512, the first line shall not be used for histogram computation. + if line size 512, ceil (512/line size) lines shall not be used for histogram computation. It's the programmer's responsibility to set the histogram computation area outside the 'clear' area.
    0=NEWENUM1 (Disable); 1=NEWENUM2 (Enable)
  [0] SEL rw — This bit shall be used to select which memory is used to store the histogram data. By selecting alternatively one or the other bit, one can double buffer the histogram output buffer. The 4 KB memory can either be read by the CPU or a DMA request.
    0=NEWENUM1 (Use Table 0 and 1 = 4 KBytes in the memory ISP5 map.); 1=NEWENUM2 (Use Table 2 and 3 = 4 KBytes in the memory ISP5 map.)
0x3F0 IPIPE_HST_MUL_R — Histogram
  [7:0] GAIN rw
0x3F4 IPIPE_HST_MUL_GR — Histogram
  [7:0] GAIN rw
0x3F8 IPIPE_HST_MUL_GB — Histogram
  [7:0] GAIN rw
0x3FC IPIPE_HST_MUL_B — Histogram
  [7:0] GAIN rw
0x400 IPIPE_BSC_EN — Boundary Signal Calculator
  [0] EN rw — The start flag of the ?Boundary Signal Calculator?.
    0=NEWENUM1 (Disable); 1=NEWENUM2 (Enable)
0x404 IPIPE_BSC_MODE — Boundary Signal Calculator
  [0] OST rw — The processing mode selection of the BSC module.
    0=NEWENUM1 (Free run); 1=NEWENUM2 (One shot)
0x408 IPIPE_BSC_TYP — Boundary Signal Calculator
  [3] CEN rw — Enable of column sampling.
    0=NEWENUM1 (Off); 1=NEWENUM2 (On)
  [2] REN rw — Enable of row sampling
    0=NEWENUM1 (Off); 1=NEWENUM2 (On)
  [1:0] COL rw — Selects the element to be summed. (Y, Cb or Cr )
    0=NEWENUM1 (Y); 1=NEWENUM2 (Cb); 3=NEWENUM4 (Reserved); 2=NEWENUM3 (Cr)
0x40C IPIPE_BSC_ROW_VCT — Boundary Signal Calculator
  [1:0] VAL rw — The number of row sum vectors. value = ROWNUM + 1 Range: 1-4
0x410 IPIPE_BSC_ROW_SHF — Boundary Signal Calculator
  [2:0] VAL rw — The down shift value for row sum vectors. Range: 0-7
0x414 IPIPE_BSC_ROW_VPOS — Boundary Signal Calculator
  [12:0] VAL rw — The vertical position of the first sampling pixel; the first row to be summed.
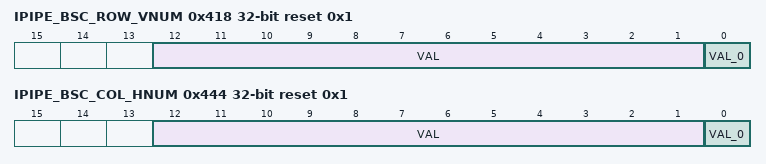
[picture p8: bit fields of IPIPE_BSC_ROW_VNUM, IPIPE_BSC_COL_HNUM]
0x418 IPIPE_BSC_ROW_VNUM reset 0x1 — Boundary Signal Calculator
  [12:1] VAL rw — The height of the area covered by a row sum vector. Height of the region = (ROW_VNUM + 1)*(ROW_VSKIP+1).IPIPE_BSC_ROW_VNUM must be odd, LSB = 1.
  [0] VAL_0 ro — The LSB must be odd.
0x41C IPIPE_BSC_ROW_VSKIP — Boundary Signal Calculator
  [4:0] VAL rw — The interval of the rows. Interval = ROWSKIPV + 1 Range: 1-32
0x420 IPIPE_BSC_ROW_HPOS — Boundary Signal Calculator
  [12:0] VAL rw — The horizontal position of the first sampling pixel; the first pixel in a row to be summed.
0x424 IPIPE_BSC_ROW_HNUM — Boundary Signal Calculator
  [12:0] VAL rw — The horizontal number of samples in the area covered by a row sum vector. Width of the region = (ROW_HNUM + 1)*(ROW_HSKIP+1).
0x428 IPIPE_BSC_ROW_HSKIP — Boundary Signal Calculator
  [4:0] VAL rw — The interval of the pixels in a row to be summed. Interval = ROWSKIPH + 1 Range: 1-32
0x42C IPIPE_BSC_COL_VCT — Boundary Signal Calculator
  [1:0] VAL rw — The number of column sum vectors. number = COLNUM + 1 Range: 1-4
0x430 IPIPE_BSC_COL_SHF — Boundary Signal Calculator
  [2:0] VAL rw — The down shift value for column sum vectors. Range: 0-7
0x434 IPIPE_BSC_COL_VPOS — Boundary Signal Calculator
  [12:0] VAL rw — The vertical position of the first sampling pixel; the first pixel in a column to be summed.
0x438 IPIPE_BSC_COL_VNUM — Boundary Signal Calculator
  [12:0] VAL rw — The vertical number of samples in the area covered by a column sum vector. Height of the region = (COL_VNUM + 1)*(COL_VSKIP+1).
0x43C IPIPE_BSC_COL_VSKIP — Boundary Signal Calculator
  [4:0] VAL rw — The interval of the pixels in a column to be summed. Interval = COLSKIPV + 1 Range: 1-32
0x440 IPIPE_BSC_COL_HPOS — Boundary Signal Calculator
  [12:0] VAL rw — The horizontal position of the first sampling pixel; the first column to be summed.
0x444 IPIPE_BSC_COL_HNUM reset 0x1 — Boundary Signal Calculator
  [12:1] VAL rw — The width of the area covered by a column sum vector. Width of the region = (COL_HNUM + 1)*(COL_HSKIP+1).IPIPE_BSC_COL_HNUM must be odd, LSB = 1.
  [0] VAL_0 ro — The LSB must be odd
0x448 IPIPE_BSC_COL_HSKIP — Boundary Signal Calculator
  [4:0] VAL rw — The interval of the columns. Interval = COL_HSKIP + 1 Range: 1-32
0x44C IPIPE_YUV_INP_OFST_Y — Offset value applied to Y input becore YUVtoRGB matrix. These values are only valid if IPIPE_FMT[FMT]=3 (YUV422 input) IPIPE_FMT[FMT2]=2 (RGB processing after YUVtoRGB conversion)
  [8:0] Y_OFST rw — Y offset value (s9) Usually zero.
0x450 IPIPE_YUV_INP_OFST_CB reset 0x180 — Offset value applied to CB input becore YUVtoRGB matrix. These values are only valid if IPIPE_FMT[FMT]=3 (YUV422 input) IPIPE_FMT[FMT2]=2 (RGB processing after YUVtoRGB conversion)
  [8:0] CB_OFST rw — Cb offset value (s9) Usually -128
0x454 IPIPE_YUV_INP_OFST_CR reset 0x180 — Offset value applied to CR input becore YUVtoRGB matrix. These values are only valid if IPIPE_FMT[FMT]=3 (YUV422 input) IPIPE_FMT[FMT2]=2 (RGB processing after YUVtoRGB conversion)
  [8:0] CR_OFST rw — Cr offset value (s9) Usually -128
